# STM32WB55 register map
File version: 2.0
CPU: CM4 r0p1, little endian, MPU, FPU, 4 interrupt priority bits
Registers are 32-bit, read-write, reset 0x0 unless marked. A register's access mark holds for its fields unless they carry their own. Offsets are from the block's base; [hi:lo] are bit positions; {n}, {i} and the like mark numbered series; 'fields as' and 'values as' point back to an identical list.

## SYSCFG — SYSCFG_VREFBUF
Base 0x40010000
0x00 MEMRMP — memory remap register
  [2:0] MEM_MODE — Memory mapping selection
    0=Main Flash memory mapped at 0x0000_0000; 1=System Flash memory mapped at 0x0000_0000; 3=SRAM (Embedded SRAM mapped at 0x0000_0000); 6=QUADSPI (QUADSPI memory mapped at 0x0000_0000)
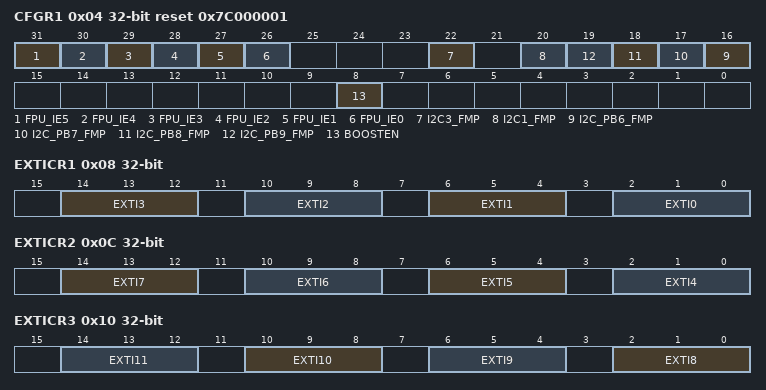
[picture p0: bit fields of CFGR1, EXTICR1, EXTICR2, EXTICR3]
0x04 CFGR1 reset 0x7C000001 — configuration register 1
  [31] FPU_IE5 — Floating Point Unit interrupts enable bits
    0=Disabled (Inexact interrupt disable); 1=Enabled (Inexact interrupt enable)
  [30] FPU_IE4 — Floating Point Unit interrupts enable bits
    0=Disabled (Input denormal interrupt disable); 1=Enabled (Input denormal interrupt enable)
  [29] FPU_IE3 — Floating Point Unit interrupts enable bits
    0=Disabled (Overflow interrupt disable); 1=Enabled (Overflow interrupt enable)
  [28] FPU_IE2 — Floating Point Unit interrupts enable bits
    0=Disabled (Underflow interrupt disable); 1=Enabled (Underflow interrupt enable)
  [27] FPU_IE1 — Floating Point Unit interrupts enable bits
    0=Disabled (Devide-by-zero interrupt disable); 1=Enabled (Devide-by-zero interrupt enable)
  [26] FPU_IE0 — Floating Point Unit interrupts enable bits
    0=Disabled (Invalid operation interrupt disable); 1=Enabled (Invalid operation interrupt enable)
  [22] I2C3_FMP — I2C3 Fast-mode Plus driving capability activation
    0=Standard (FM+ mode is controlled by I2C_Pxx_FMP bits only); 1=FMP (FM+ mode is enabled on all I2C3 pins selected through selection bits in GPIOx_AFR registers)
  [20] I2C1_FMP — I2C1 Fast-mode Plus driving capability activation
    0=Standard (FM+ mode is controlled by I2C_Pxx_FMP bits only); 1=FMP (FM+ mode is enabled on all I2C1 pins selected through selection bits in GPIOx_AFR registers)
  [n+10] I2C_PB{n}_FMP (n=6..9) — Fast-mode Plus (Fm+) driving capability activation on PB{n}
    0=Standard (PB{n} pin operate in standard mode); 1=FMP (I2C FM+ mode enabled on PB{n} and the Speed control is bypassed)
  [8] BOOSTEN — I/O analog switch voltage booster enable
    0=Disabled (I/O analog switches are supplied by VDDA voltage. This is the recommended configuration when using the ADC in high VDDA voltage operation); 1=Enabled (I/O analog switches are supplied by a dedicated voltage booster (supplied by VDD). This is the recommended configuration when using the ADC in low VDDA voltage operation)
0x08 EXTICR1 — external interrupt configuration register 1
  [14:12] EXTI3 — EXTI 3 configuration bits
    0=PA (Select PAx as the source input for the EXTIx external interrupt); 1=PB (Select PBx as the source input for the EXTIx external interrupt); 2=PC (Select PCx as the source input for the EXTIx external interrupt); 3=PD (Select PDx as the source input for the EXTIx external interrupt); 4=PE (Select PEx as the source input for the EXTIx external interrupt); 7=PH (Select PHx as the source input for the EXTIx external interrupt)
  [10:8] EXTI2 — EXTI 2 configuration bits
    0=PA (Select PAx as the source input for the EXTIx external interrupt); 1=PB (Select PBx as the source input for the EXTIx external interrupt); 2=PC (Select PCx as the source input for the EXTIx external interrupt); 3=PD (Select PDx as the source input for the EXTIx external interrupt); 4=PE (Select PEx as the source input for the EXTIx external interrupt)
  [6:4] EXTI1 — EXTI 1 configuration bits
    values as EXTI3
  [2:0] EXTI0 — EXTI 0 configuration bits
    values as EXTI3
0x0C EXTICR2 — external interrupt configuration register 2
  [14:12] EXTI7 — EXTI 7 configuration bits
    0=PA (Select PAx as the source input for the EXTIx external interrupt); 1=PB (Select PBx as the source input for the EXTIx external interrupt); 2=PC (Select PCx as the source input for the EXTIx external interrupt); 3=PD (Select PDx as the source input for the EXTIx external interrupt)
  [10:8] EXTI6 — EXTI 6 configuration bits
    values as EXTI7
  [6:4] EXTI5 — EXTI 5 configuration bits
    values as EXTI7
  [2:0] EXTI4 — EXTI 4 configuration bits
    values as EXTICR1.EXTI2
0x10 EXTICR3 — external interrupt configuration register 3
  [all] fields
    values as EXTICR2.EXTI7
  [4n-30:4n-32] EXTI{n} (n=8..11) — EXTI {n} configuration bits
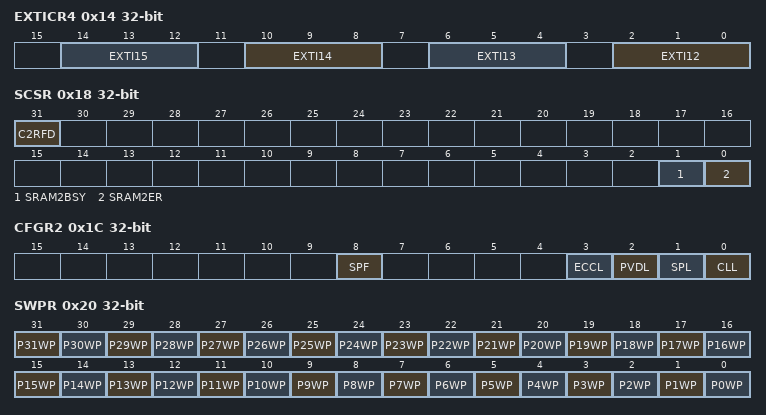
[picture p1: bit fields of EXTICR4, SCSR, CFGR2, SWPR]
0x14 EXTICR4 — external interrupt configuration register 4
  [all] fields
    values as EXTICR2.EXTI7
  [4n-46:4n-48] EXTI{n} (n=12..15) — EXTI{n} configuration bits
0x18 SCSR access per field
  [31] C2RFD rw — CPU2 SRAM fetch (execution) disable.
    0=Disabled (CPU2 fetch from SRAM1, SRAM2a and SRAM2b enabled); 1=Enabled (CPU2 fetch from SRAM1, SRAM2a and SRAM2b disabled)
  [1] SRAM2BSY ro — SRAM2 busy by erase operation
    0=Idle (No SRAM2 or PKA RAM erase operation is ongoing); 1=Busy (SRAM2 and/or PKA RAM erase operation is ongoing)
  [0] SRAM2ER rw — SRAM2 Erase
    on write: 1=Erase (Start SRAM2 erase operation)
0x1C CFGR2
  [8] SPF — SRAM2 parity error flag
    on read: 0=Nominal (No SRAM2 parity error detected); 1=Error (SRAM2 parity error detected) | on write: 1=Clear SRAM2 parity error flag
  [3] ECCL — ECC Lock
    on read: 0=Disconnected (ECC error disconnected from TIM1/16/17 break input); 1=Connected (ECC error connected to TIM1/16/17 break input) | on write: 1=Connect ECC error to TIM1/16/17 break input
  [2] PVDL — PVD lock enable bit
    on read: 0=Disconnected (PVD interrupt disconnected from TIM1/16/17 break input. PVDE and PLS[2:0] bits can be programmed by the application); 1=Connected (PVD interrupt connected to TIM1/16/17 break input. PVDE and PLS[2:0] bits are read only) | on write: 1=Connect PVD interretup to TIM1/16/17 break input
  [1] SPL — SRAM2 parity lock bit
    on read: 0=Disconnected (SRAM2 parity error signal disconnected from TIM1/16/17 break input); 1=Connected (SRAM2 parity error signal connected to TIM1/16/17 break input) | on write: 1=Connect SRAM2 parity error signal to TIM1/16/17 break input
  [0] CLL — Cortex-M4 LOCKUP (Hardfault) output enable bit
    on read: 0=Disconnected (CPU LOCKUP output disconnected from TIM1/16/17 break input); 1=Connected (CPU LOCKUP output connected to TIM1/16/17 break input) | on write: 1=Connect CPU LOCKUP output to TIM1/16/17 break input
0x20 SWPR wo — SRAM2 write protection register
  [all] fields
    0=Disabled (SRAM2 1 KB page protection disabled); 1=Enabled (SRAM2 1 KB page protection enabled)
  [31] P31WP — SRAM2 page 31 write protection
  [n] P{n}WP (n=0..30)
0x24 SKR wo
  [7:0] KEY — SRAM2 write protection key for software erase
    17=WriteProtect (Activate SRAM2ER bits write protection); 83=Step 2 to remove SRAM2ER bits write protection; 202=Step 1 to remove SRAM2ER bits write protection
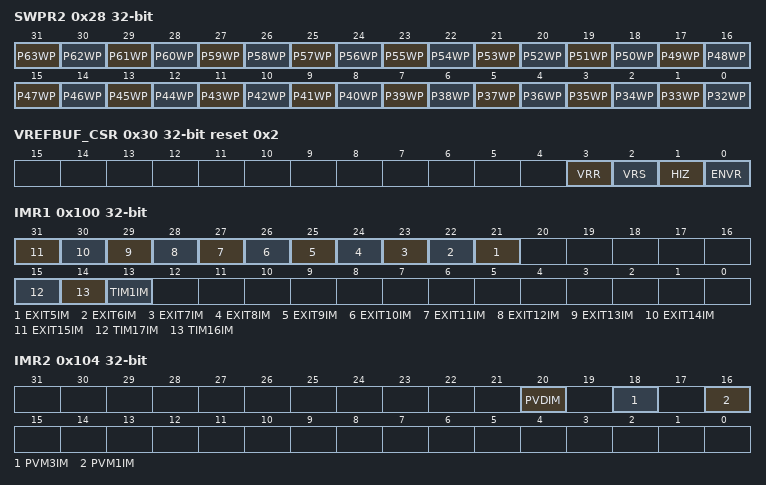
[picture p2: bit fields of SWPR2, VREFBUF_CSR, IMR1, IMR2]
0x28 SWPR2 wo — SRAM2 write protection register 2
  [all] fields
    values as the fields of SWPR
  [31] P63WP — SRAM2 page 63 write protection
  [n-32] P{n}WP (n=32..62)
0x30 VREFBUF_CSR access per field reset 0x2 — VREF control and status register
  [3] VRR ro — Voltage reference buffer ready
  [2] VRS rw — Voltage reference scale
  [1] HIZ rw — High impedance mode
  [0] ENVR rw — Voltage reference buffer enable
0x34 VREFBUF_CCR — calibration control register
  [5:0] TRIM — Trimming code
0x100 IMR1 — CPU1 interrupt mask register 1
  [all] fields
    0=Unmasked (Peripheral interrupt forwarded to CPU1); 1=Masked (Peripheral interrupt to CPU1 masked)
  [n+16] EXIT{n}IM (n=5..15) — Peripheral EXIT{n} interrupt mask to CPU1
  [15] TIM17IM — Peripheral TIM17 interrupt mask to CPU1
  [14] TIM16IM — Peripheral TIM16 interrupt mask to CPU1
  [13] TIM1IM — Peripheral TIM1 interrupt mask to CPU1
0x104 IMR2 — CPU1 interrupt mask register 2
  [all] fields
    values as the fields of IMR1
  [20] PVDIM — Peripheral PVD interrupt mask to CPU1
  [18] PVM3IM — Peripheral PVM3 interrupt mask to CPU1
  [16] PVM1IM — Peripheral PVM1 interrupt mask to CPU1
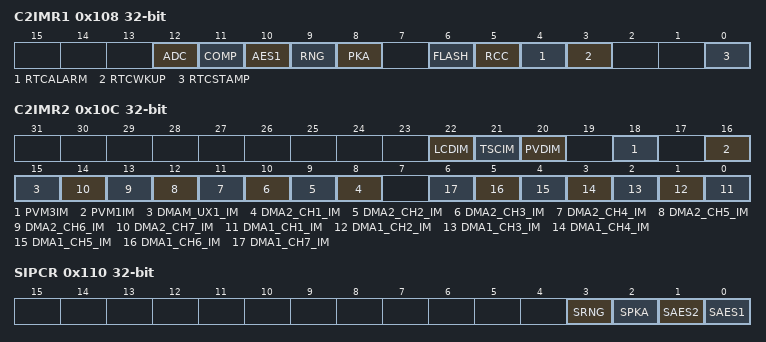
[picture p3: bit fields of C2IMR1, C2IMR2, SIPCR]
0x108 C2IMR1 — CPU2 interrupt mask register 1
  [all] fields
    0=Unmasked (Peripheral interrupt forwarded to CPU2); 1=Masked (Peripheral interrupt to CPU2 masked)
  [12] ADC — Peripheral ADC interrupt mask to CPU2
  [11] COMP — Peripheral COMP interrupt mask to CPU2
  [10] AES1 — Peripheral AES1 interrupt mask to CPU2
  [9] RNG — Peripheral RNG interrupt mask to CPU2
  [8] PKA — Peripheral PKA interrupt mask to CPU2
  [6] FLASH — Peripheral FLASH interrupt mask to CPU2
  [5] RCC — Peripheral RCC interrupt mask to CPU2
  [4] RTCALARM — Peripheral RTCALARM interrupt mask to CPU2
  [3] RTCWKUP — Peripheral RTCWKUP interrupt mask to CPU2
  [0] RTCSTAMP — Peripheral RTCSTAMP interrupt mask to CPU2
0x10C C2IMR2 — CPU2 interrupt mask register 1
  [all] fields
    values as the fields of C2IMR1
  [22] LCDIM — Peripheral LCDIM interrupt mask to CPU1
  [21] TSCIM — Peripheral TSCIM interrupt mask to CPU1
  [20] PVDIM — Peripheral PVDIM interrupt mask to CPU1
  [18] PVM3IM — Peripheral PVM3IM interrupt mask to CPU1
  [16] PVM1IM — Peripheral PVM1IM interrupt mask to CPU1
  [15] DMAM_UX1_IM — Peripheral DMAM UX1 interrupt mask to CPU1
  [n+7] DMA2_CH{n}_IM (n=1..7) — Peripheral DMA2 CH{n} interrupt mask to CPU1
  [n-1] DMA1_CH{n}_IM (n=1..7) — Peripheral DMA1 CH{n} interrupt mask to CPU2
0x110 SIPCR — secure IP control register
  [3] SRNG — Enable True RNG security
    0=Disabled (True RNG security disabled); 1=Enabled (True RNG security enabled)
  [2] SPKA — Enable PKA security
    0=Disabled (PKA security disabled); 1=Enabled (PKA security enabled)
  [1] SAES2 — Enable AES2 security.
    0=Disabled (AES2 security disabled); 1=Enabled (AES2 security enabled)
  [0] SAES1 — Enable AES1 KEY[7:0] security.
    0=Disabled (AES1 KEY[7:0] security disabled); 1=Enabled (AES1 KEY[7:0] security enabled)
